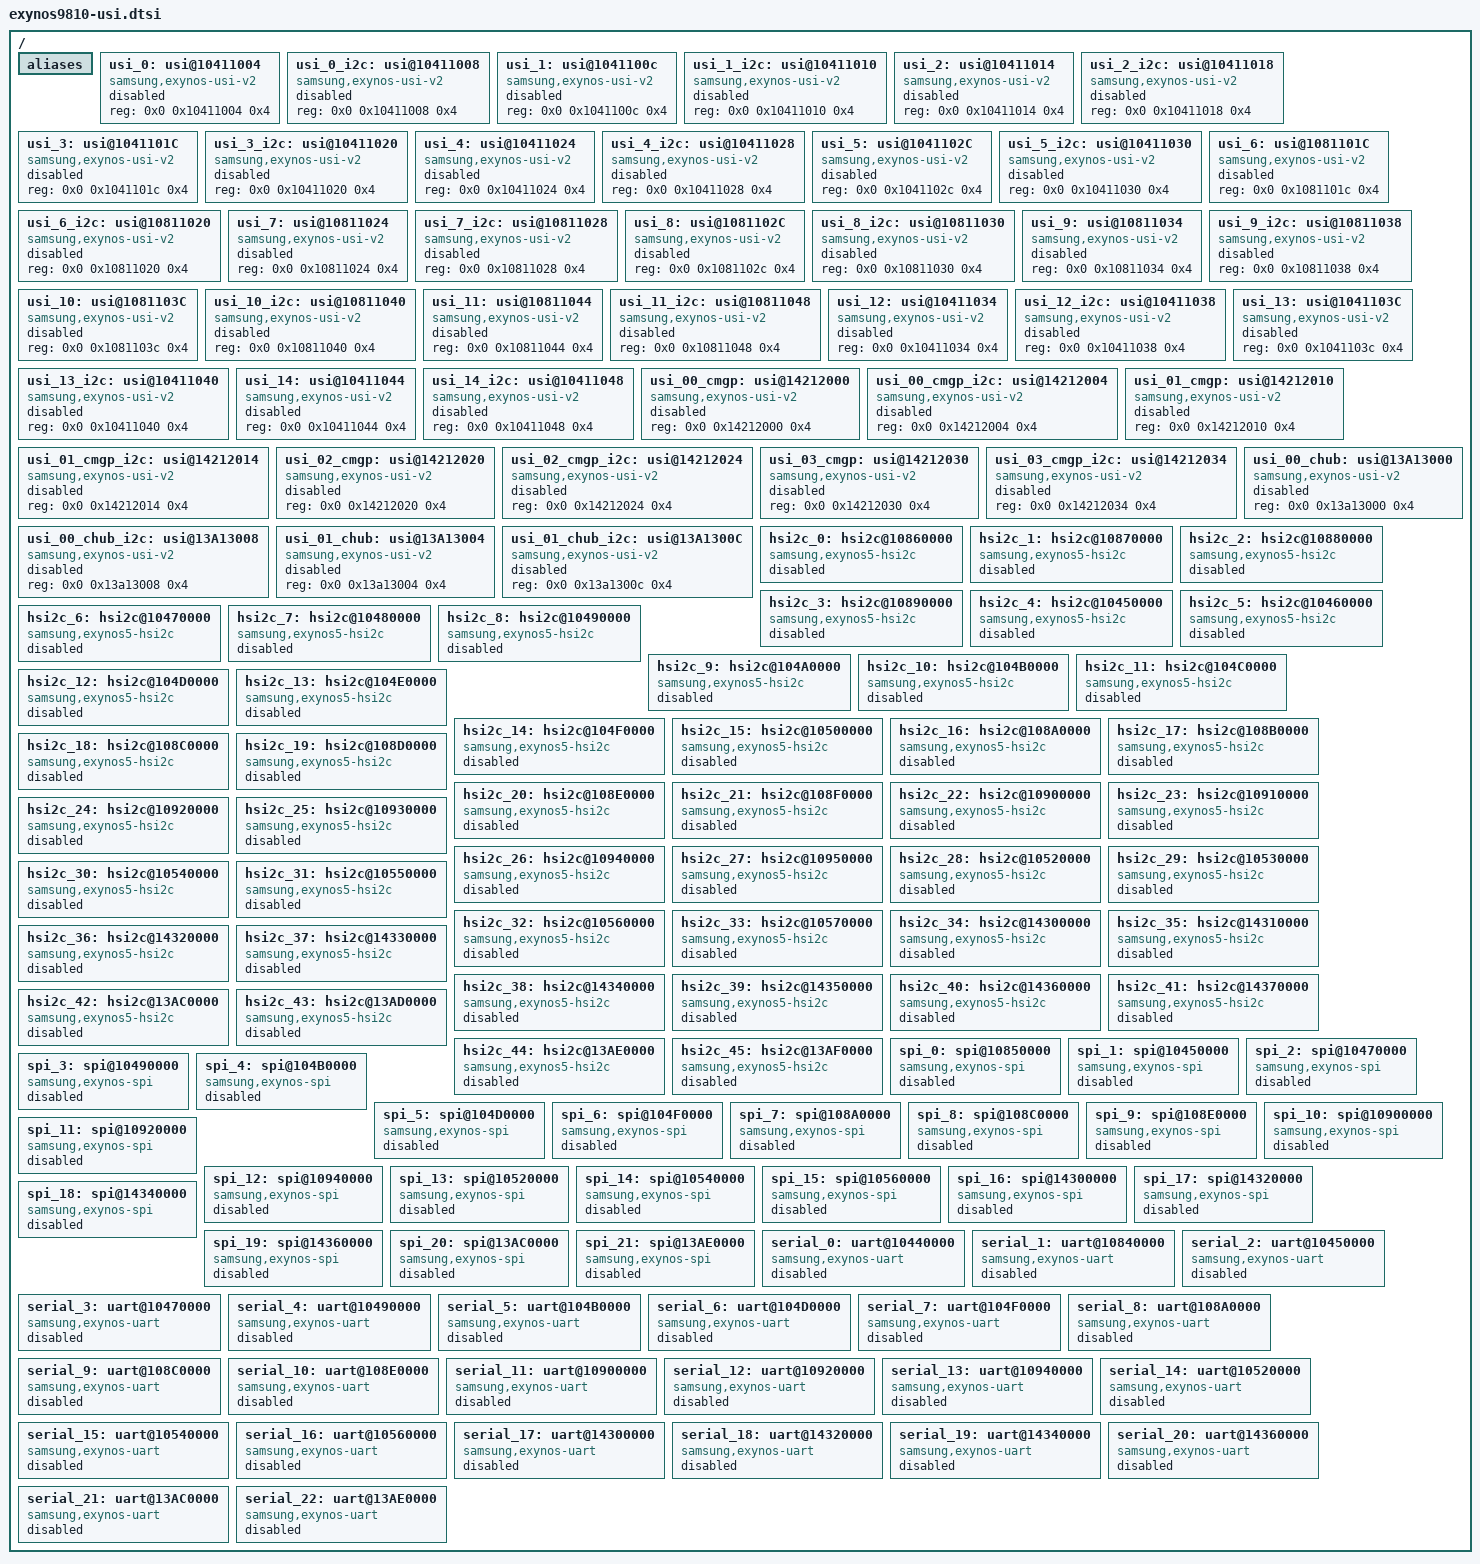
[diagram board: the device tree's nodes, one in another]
/*
 * SAMSUNG EXYNOS9810 SoC device tree source
 *
 * Copyright (c) 2017 Samsung Electronics Co., Ltd.
 *		http://www.samsung.com
 *
 * SAMSUNG EXYNOS9810 SoC device nodes are listed in this file.
 * EXYNOS9810 based board files can include this file and provide
 * values for board specfic bindings.
 *
 * This program is free software; you can redistribute it and/or modify
 * it under the terms of the GNU General Public License version 2 as
 * published by the Free Software Foundation.
 */

/ {
	aliases {
		usi0 = &usi_0;
		usi1 = &usi_0_i2c;
		usi2 = &usi_1;
		usi3 = &usi_1_i2c;
		usi4 = &usi_2;
		usi5 = &usi_2_i2c;
		usi6 = &usi_3;
		usi7 = &usi_3_i2c;
		usi8 = &usi_4;
		usi9 = &usi_4_i2c;
		usi10 = &usi_5;
		usi11 = &usi_5_i2c;
		usi12 = &usi_6;
		usi13 = &usi_6_i2c;
		usi14 = &usi_7;
		usi15 = &usi_7_i2c;
		usi16 = &usi_8;
		usi17 = &usi_8_i2c;
		usi18 = &usi_9;
		usi19 = &usi_9_i2c;
		usi20 = &usi_10;
		usi21 = &usi_10_i2c;
		usi22 = &usi_11;
		usi23 = &usi_11_i2c;
		usi24 = &usi_12;
		usi25 = &usi_12_i2c;
		usi26 = &usi_13;
		usi27 = &usi_13_i2c;
		usi28 = &usi_14;
		usi29 = &usi_14_i2c;
		usi30 = &usi_00_cmgp;
		usi31 = &usi_00_cmgp_i2c;
		usi32 = &usi_01_cmgp;
		usi33 = &usi_01_cmgp_i2c;
		usi34 = &usi_02_cmgp;
		usi35 = &usi_02_cmgp_i2c;
		usi36 = &usi_03_cmgp;
		usi37 = &usi_03_cmgp_i2c;
		usi38 = &usi_00_chub;
		usi39 = &usi_00_chub_i2c;
		usi40 = &usi_01_chub;
		usi41 = &usi_01_chub_i2c;
		hsi2c0 = &hsi2c_0;
		hsi2c1 = &hsi2c_1;
		hsi2c2 = &hsi2c_2;
		hsi2c3 = &hsi2c_3;
		hsi2c4 = &hsi2c_4;
		hsi2c5 = &hsi2c_5;
		hsi2c6 = &hsi2c_6;
		hsi2c7 = &hsi2c_7;
		hsi2c8 = &hsi2c_8;
		hsi2c9 = &hsi2c_9;
		hsi2c10 = &hsi2c_10;
		hsi2c11 = &hsi2c_11;
		hsi2c12 = &hsi2c_12;
		hsi2c13 = &hsi2c_13;
		hsi2c14 = &hsi2c_14;
		hsi2c15 = &hsi2c_15;
		hsi2c16 = &hsi2c_16;
		hsi2c17 = &hsi2c_17;
		hsi2c18 = &hsi2c_18;
		hsi2c19 = &hsi2c_19;
		hsi2c20 = &hsi2c_20;
		hsi2c21 = &hsi2c_21;
		hsi2c22 = &hsi2c_22;
		hsi2c23 = &hsi2c_23;
		hsi2c24 = &hsi2c_24;
		hsi2c25 = &hsi2c_25;
		hsi2c26 = &hsi2c_26;
		hsi2c27 = &hsi2c_27;
		hsi2c28 = &hsi2c_28;
		hsi2c29 = &hsi2c_29;
		hsi2c30 = &hsi2c_30;
		hsi2c31 = &hsi2c_31;
		hsi2c32 = &hsi2c_32;
		hsi2c33 = &hsi2c_33;
		hsi2c34 = &hsi2c_34;
		hsi2c35 = &hsi2c_35;
		hsi2c36 = &hsi2c_36;
		hsi2c37 = &hsi2c_37;
		hsi2c38 = &hsi2c_38;
		hsi2c39 = &hsi2c_39;
		hsi2c40 = &hsi2c_40;
		hsi2c41 = &hsi2c_41;
		hsi2c42 = &hsi2c_42;
		hsi2c43 = &hsi2c_43;
		hsi2c44 = &hsi2c_44;
		hsi2c45 = &hsi2c_45;
		spi0 = &spi_0;
		spi1 = &spi_1;
		spi2 = &spi_2;
		spi3 = &spi_3;
		spi4 = &spi_4;
		spi5 = &spi_5;
		spi6 = &spi_6;
		spi7 = &spi_7;
		spi8 = &spi_8;
		spi9 = &spi_9;
		spi10 = &spi_10;
		spi11 = &spi_11;
		spi12 = &spi_12;
		spi13 = &spi_13;
		spi14 = &spi_14;
		spi15 = &spi_15;
		spi16 = &spi_16;
		spi17 = &spi_17;
		spi18 = &spi_18;
		spi19 = &spi_19;
		spi20 = &spi_20;
		spi21 = &spi_21;
		uart0 = &serial_0;
		uart1 = &serial_1;
		uart2 = &serial_2;
		uart3 = &serial_3;
		uart4 = &serial_4;
		uart5 = &serial_5;
		uart6 = &serial_6;
		uart7 = &serial_7;
		uart8 = &serial_8;
		uart9 = &serial_9;
		uart10 = &serial_10;
		uart11 = &serial_11;
		uart12 = &serial_12;
		uart13 = &serial_13;
		uart14 = &serial_14;
		uart15 = &serial_15;
		uart16 = &serial_16;
		uart17 = &serial_17;
		uart18 = &serial_18;
		uart19 = &serial_19;
		uart20 = &serial_20;
		uart21 = &serial_21;
		uart22 = &serial_22;
	};

	/* USI_00 */
	usi_0: usi@10411004 {
		compatible = "samsung,exynos-usi-v2";
		reg = <0x0 0x10411004 0x4>;
		/*	usi_mode_v2 = "i2c" or "spi" or "uart"	*/
		status = "disabled";
	};

	/* USI_00_I2C */
	usi_0_i2c: usi@10411008 {
		compatible = "samsung,exynos-usi-v2";
		reg = <0x0 0x10411008 0x4>;
		/*	usi_mode_v2 = "i2c" */
		status = "disabled";
	};

	/* USI_01 */
	usi_1: usi@1041100c {
		compatible = "samsung,exynos-usi-v2";
		reg = <0x0 0x1041100c 0x4>;
		/*	usi_mode_v2 = "i2c" or "spi" or "uart"	*/
		status = "disabled";
	};

	/* USI_01_I2C */
	usi_1_i2c: usi@10411010 {
		compatible = "samsung,exynos-usi-v2";
		reg = <0x0 0x10411010 0x4>;
		/*	usi_mode_v2 = "i2c" */
		status = "disabled";
	};

	/* USI_02 */
	usi_2: usi@10411014 {
		compatible = "samsung,exynos-usi-v2";
		reg = <0x0 0x10411014 0x4>;
		/*	usi_mode_v2 = "i2c" or "spi" or "uart"	*/
		status = "disabled";
	};

	/* USI_02_I2C */
	usi_2_i2c: usi@10411018 {
		compatible = "samsung,exynos-usi-v2";
		reg = <0x0 0x10411018 0x4>;
		/*	usi_mode_v2 = "i2c" */
		status = "disabled";
	};

	/* USI_03 */
	usi_3: usi@1041101C {
		compatible = "samsung,exynos-usi-v2";
		reg = <0x0 0x1041101c 0x4>;
		/*	usi_mode_v2 = "i2c" or "spi" or "uart"	*/
		status = "disabled";
	};

	/* USI_03_I2C */
	usi_3_i2c: usi@10411020 {
		compatible = "samsung,exynos-usi-v2";
		reg = <0x0 0x10411020 0x4>;
		/*	usi_mode_v2 = "i2c" */
		status = "disabled";
	};

	/* USI_04 */
	usi_4: usi@10411024 {
		compatible = "samsung,exynos-usi-v2";
		reg = <0x0 0x10411024 0x4>;
		/*	usi_mode_v2 = "i2c" or "spi" or "uart"	*/
		status = "disabled";
	};

	/* USI_04_I2C */
	usi_4_i2c: usi@10411028 {
		compatible = "samsung,exynos-usi-v2";
		reg = <0x0 0x10411028 0x4>;
		/*	usi_mode_v2 = "i2c" */
		status = "disabled";
	};

	/* USI_05 */
	usi_5: usi@1041102C {
		compatible = "samsung,exynos-usi-v2";
		reg = <0x0 0x1041102c 0x4>;
		/*	usi_mode_v2 = "i2c" or "spi" or "uart"	*/
		status = "disabled";
	};

	/* USI_05_I2C */
	usi_5_i2c: usi@10411030 {
		compatible = "samsung,exynos-usi-v2";
		reg = <0x0 0x10411030 0x4>;
		/*	usi_mode_v2 = "i2c" */
		status = "disabled";
	};

	/* USI_06 */
	usi_6: usi@1081101C {
		compatible = "samsung,exynos-usi-v2";
		reg = <0x0 0x1081101c 0x4>;
		/*	usi_mode_v2 = "i2c" or "spi" or "uart"	*/
		status = "disabled";
	};

	/* USI_06_I2C */
	usi_6_i2c: usi@10811020 {
		compatible = "samsung,exynos-usi-v2";
		reg = <0x0 0x10811020 0x4>;
		/*	usi_mode_v2 = "i2c" */
		status = "disabled";
	};

	/* USI_07 */
	usi_7: usi@10811024 {
		compatible = "samsung,exynos-usi-v2";
		reg = <0x0 0x10811024 0x4>;
		/*	usi_mode_v2 = "i2c" or "spi" or "uart"	*/
		status = "disabled";
	};

	/* USI_07_I2C */
	usi_7_i2c: usi@10811028 {
		compatible = "samsung,exynos-usi-v2";
		reg = <0x0 0x10811028 0x4>;
		/*	usi_mode_v2 = "i2c" */
		status = "disabled";
	};

	/* USI_08 */
	usi_8: usi@1081102C {
		compatible = "samsung,exynos-usi-v2";
		reg = <0x0 0x1081102c 0x4>;
		/*	usi_mode_v2 = "i2c" or "spi" or "uart"	*/
		status = "disabled";
	};

	/* USI_08_I2C */
	usi_8_i2c: usi@10811030 {
		compatible = "samsung,exynos-usi-v2";
		reg = <0x0 0x10811030 0x4>;
		/*	usi_mode_v2 = "i2c" */
		status = "disabled";
	};

	/* USI_09 */
	usi_9: usi@10811034 {
		compatible = "samsung,exynos-usi-v2";
		reg = <0x0 0x10811034 0x4>;
		/*	usi_mode_v2 = "i2c" or "spi" or "uart"	*/
		status = "disabled";
	};

	/* USI_09_I2C */
	usi_9_i2c: usi@10811038 {
		compatible = "samsung,exynos-usi-v2";
		reg = <0x0 0x10811038 0x4>;
		/*	usi_mode_v2 = "i2c" */
		status = "disabled";
	};

	/* USI_10 */
	usi_10: usi@1081103C {
		compatible = "samsung,exynos-usi-v2";
		reg = <0x0 0x1081103c 0x4>;
		/*	usi_mode_v2 = "i2c" or "spi" or "uart"	*/
		status = "disabled";
	};

	/* USI_10_I2C */
	usi_10_i2c: usi@10811040 {
		compatible = "samsung,exynos-usi-v2";
		reg = <0x0 0x10811040 0x4>;
		/*	usi_mode_v2 = "i2c" */
		status = "disabled";
	};

	/* USI_11 */
	usi_11: usi@10811044 {
		compatible = "samsung,exynos-usi-v2";
		reg = <0x0 0x10811044 0x4>;
		/*	usi_mode_v2 = "i2c" or "spi" or "uart"	*/
		status = "disabled";
	};

	/* USI_11_I2C */
	usi_11_i2c: usi@10811048 {
		compatible = "samsung,exynos-usi-v2";
		reg = <0x0 0x10811048 0x4>;
		/*	usi_mode_v2 = "i2c" */
		status = "disabled";
	};

	/* USI_12 */
	usi_12: usi@10411034 {
		compatible = "samsung,exynos-usi-v2";
		reg = <0x0 0x10411034 0x4>;
		/*	usi_mode_v2 = "i2c" or "spi" or "uart"	*/
		status = "disabled";
	};

	/* USI_12_I2C */
	usi_12_i2c: usi@10411038 {
		compatible = "samsung,exynos-usi-v2";
		reg = <0x0 0x10411038 0x4>;
		/*	usi_mode_v2 = "i2c" */
		status = "disabled";
	};

	/* USI_13 */
	usi_13: usi@1041103C {
		compatible = "samsung,exynos-usi-v2";
		reg = <0x0 0x1041103c 0x4>;
		/*	usi_mode_v2 = "i2c" or "spi" or "uart"	*/
		status = "disabled";
	};

	/* USI_13_I2C */
	usi_13_i2c: usi@10411040 {
		compatible = "samsung,exynos-usi-v2";
		reg = <0x0 0x10411040 0x4>;
		/*	usi_mode_v2 = "i2c" */
		status = "disabled";
	};

	/* USI_14 */
	usi_14: usi@10411044 {
		compatible = "samsung,exynos-usi-v2";
		reg = <0x0 0x10411044 0x4>;
		/*	usi_mode_v2 = "i2c" or "spi" or "uart"	*/
		status = "disabled";
	};

	/* USI_14_I2C */
	usi_14_i2c: usi@10411048 {
		compatible = "samsung,exynos-usi-v2";
		reg = <0x0 0x10411048 0x4>;
		/*	usi_mode_v2 = "i2c" */
		status = "disabled";
	};

	/* USI_00_CMGP */
	usi_00_cmgp: usi@14212000 {
		compatible = "samsung,exynos-usi-v2";
		reg = <0x0 0x14212000 0x4>;
		/*	usi_mode_v2 = "i2c" or "spi" or "uart"	*/
		status = "disabled";
	};

	/* USI_00_CMGP_I2C */
	usi_00_cmgp_i2c: usi@14212004 {
		compatible = "samsung,exynos-usi-v2";
		reg = <0x0 0x14212004 0x4>;
		/*	usi_mode_v2 = "i2c" */
		status = "disabled";
	};

	/* USI_01_CMGP */
	usi_01_cmgp: usi@14212010 {
		compatible = "samsung,exynos-usi-v2";
		reg = <0x0 0x14212010 0x4>;
		/*	usi_mode_v2 = "i2c" or "spi" or "uart"	*/
		status = "disabled";
	};

	/* USI_01_CMGP_I2C */
	usi_01_cmgp_i2c: usi@14212014 {
		compatible = "samsung,exynos-usi-v2";
		reg = <0x0 0x14212014 0x4>;
		/*	usi_mode_v2 = "i2c" */
		status = "disabled";
	};

	/* USI_02_CMGP */
	usi_02_cmgp: usi@14212020 {
		compatible = "samsung,exynos-usi-v2";
		reg = <0x0 0x14212020 0x4>;
		/*	usi_mode_v2 = "i2c" or "spi" or "uart"	*/
		status = "disabled";
	};

	/* USI_02_CMGP_I2C */
	usi_02_cmgp_i2c: usi@14212024 {
		compatible = "samsung,exynos-usi-v2";
		reg = <0x0 0x14212024 0x4>;
		/*	usi_mode_v2 = "i2c" */
		status = "disabled";
	};

	/* USI_03_CMGP */
	usi_03_cmgp: usi@14212030 {
		compatible = "samsung,exynos-usi-v2";
		reg = <0x0 0x14212030 0x4>;
		/*	usi_mode_v2 = "i2c" or "spi" or "uart"	*/
		status = "disabled";
	};

	/* USI_03_CMGP_I2C */
	usi_03_cmgp_i2c: usi@14212034 {
		compatible = "samsung,exynos-usi-v2";
		reg = <0x0 0x14212034 0x4>;
		/*	usi_mode_v2 = "i2c" */
		status = "disabled";
	};

	/* USI_00_CHUB */
	usi_00_chub: usi@13A13000 {
		compatible = "samsung,exynos-usi-v2";
		reg = <0x0 0x13a13000 0x4>;
		/*	usi_mode_v2 = "i2c" */
		status = "disabled";
	};

	/* USI_00_CHUB_I2C */
	usi_00_chub_i2c: usi@13A13008 {
		compatible = "samsung,exynos-usi-v2";
		reg = <0x0 0x13a13008 0x4>;
		/*	usi_mode_v2 = "i2c" */
		status = "disabled";
	};

	/* USI_01_CHUB */
	usi_01_chub: usi@13A13004 {
		compatible = "samsung,exynos-usi-v2";
		reg = <0x0 0x13a13004 0x4>;
		/*	usi_mode_v2 = "i2c" */
		status = "disabled";
	};

	/* USI_01_CHUB_I2C */
	usi_01_chub_i2c: usi@13A1300C {
		compatible = "samsung,exynos-usi-v2";
		reg = <0x0 0x13a1300c 0x4>;
		/*	usi_mode_v2 = "i2c" */
		status = "disabled";
	};

	/* PERIC1 CAM0 */
	hsi2c_0: hsi2c@10860000 {
		compatible = "samsung,exynos5-hsi2c";
		samsung,check-transdone-int;
		default-clk = <200000000>;
		reg = <0x0 0x10860000 0x1000>;
		interrupts = <0 INTREQ__I2C_CAM0 0>;
		#address-cells = <1>;
		#size-cells = <0>;
		pinctrl-names = "default";
		pinctrl-0 = <&hsi2c0_bus>;
		clocks = <&clock I2C_CAM0>, <&clock GATE_I2C_CAM0>;
		clock-names = "rate_hsi2c", "gate_hsi2c";
		samsung,scl-clk-stretching;
		samsung,usi-i2c-v2;
		gpio_scl= <&gpc0 0 0x1>;
		gpio_sda= <&gpc0 1 0x1>;
		status = "disabled";
	};

	/* PERI1 CAM1 */
	hsi2c_1: hsi2c@10870000 {
		compatible = "samsung,exynos5-hsi2c";
		samsung,check-transdone-int;
		default-clk = <200000000>;
		reg = <0x0 0x10870000 0x1000>;
		interrupts = <0 INTREQ__I2C_CAM1 0>;
		#address-cells = <1>;
		#size-cells = <0>;
		pinctrl-names = "default";
		pinctrl-0 = <&hsi2c1_bus>;
		clocks = <&clock I2C_CAM1>, <&clock GATE_I2C_CAM1>;
		clock-names = "rate_hsi2c", "gate_hsi2c";
		samsung,scl-clk-stretching;
		samsung,usi-i2c-v2;
		gpio_scl= <&gpc0 2 0x1>;
		gpio_sda= <&gpc0 3 0x1>;
		status = "disabled";
	};

	/* PERI1 CAM2 */
	hsi2c_2: hsi2c@10880000 {
		compatible = "samsung,exynos5-hsi2c";
		samsung,check-transdone-int;
		default-clk = <200000000>;
		reg = <0x0 0x10880000 0x1000>;
		interrupts = <0 INTREQ__I2C_CAM2 0>;
		#address-cells = <1>;
		#size-cells = <0>;
		pinctrl-names = "default";
		pinctrl-0 = <&hsi2c2_bus>;
		clocks = <&clock I2C_CAM2>, <&clock GATE_I2C_CAM2>;
		clock-names = "rate_hsi2c", "gate_hsi2c";
		samsung,scl-clk-stretching;
		samsung,usi-i2c-v2;
		gpio_scl= <&gpc0 4 0x1>;
		gpio_sda= <&gpc0 5 0x1>;
		status = "disabled";
	};

	/* PERI1 CAM3 */
	hsi2c_3: hsi2c@10890000 {
		compatible = "samsung,exynos5-hsi2c";
		samsung,check-transdone-int;
		default-clk = <200000000>;
		reg = <0x0 0x10890000 0x1000>;
		interrupts = <0 INTREQ__I2C_CAM3 0>;
		#address-cells = <1>;
		#size-cells = <0>;
		pinctrl-names = "default";
		pinctrl-0 = <&hsi2c3_bus>;
		clocks = <&clock I2C_CAM3>, <&clock GATE_I2C_CAM3>;
		clock-names = "rate_hsi2c", "gate_hsi2c";
		samsung,scl-clk-stretching;
		samsung,usi-i2c-v2;
		gpio_scl= <&gpc0 6 0x1>;
		gpio_sda= <&gpc0 7 0x1>;
		status = "disabled";
	};

	/* USI00_USI */
	hsi2c_4: hsi2c@10450000 {
		compatible = "samsung,exynos5-hsi2c";
		samsung,check-transdone-int;
		default-clk = <200000000>;
		reg = <0x0 0x10450000 0x1000>;
		interrupts = <0 INTREQ__USI00_USI 0>;
		#address-cells = <1>;
		#size-cells = <0>;
		pinctrl-names = "default";
		pinctrl-0 = <&hsi2c4_bus>;
		clocks = <&clock USI00>, <&clock GATE_USI00>;
		clock-names = "rate_hsi2c", "gate_hsi2c";
		samsung,scl-clk-stretching;
		samsung,usi-i2c-v2;
		gpio_scl= <&gpp0 0 0x1>;
		gpio_sda= <&gpp0 1 0x1>;
		status = "disabled";
	};

	/* USI00_USI_I2C */
	hsi2c_5: hsi2c@10460000 {
		compatible = "samsung,exynos5-hsi2c";
		samsung,check-transdone-int;
		default-clk = <200000000>;
		reg = <0x0 0x10460000 0x1000>;
		interrupts = <0 INTREQ__USI00_I2C 0>;
		#address-cells = <1>;
		#size-cells = <0>;
		pinctrl-names = "default";
		pinctrl-0 = <&hsi2c5_bus>;
		clocks = <&clock PERIC0_USI_I2C>, <&clock GATE_USI00_I2C>;
		clock-names = "rate_hsi2c", "gate_hsi2c";
		samsung,scl-clk-stretching;
		samsung,usi-i2c-v2;
		gpio_scl= <&gpp0 2 0x1>;
		gpio_sda= <&gpp0 3 0x1>;
		status = "disabled";
	};

	/* USI01_USI */
	hsi2c_6: hsi2c@10470000 {
		compatible = "samsung,exynos5-hsi2c";
		samsung,check-transdone-int;
		default-clk = <200000000>;
		reg = <0x0 0x10470000 0x1000>;
		interrupts = <0 INTREQ__USI01_USI 0>;
		#address-cells = <1>;
		#size-cells = <0>;
		pinctrl-names = "default";
		pinctrl-0 = <&hsi2c6_bus>;
		clocks = <&clock USI01>, <&clock GATE_USI01>;
		clock-names = "rate_hsi2c", "gate_hsi2c";
		samsung,scl-clk-stretching;
		samsung,usi-i2c-v2;
		gpio_scl= <&gpp0 4 0x1>;
		gpio_sda= <&gpp0 5 0x1>;
		status = "disabled";
	};

	/* USI01_USI_I2C */
	hsi2c_7: hsi2c@10480000 {
		compatible = "samsung,exynos5-hsi2c";
		samsung,check-transdone-int;
		default-clk = <200000000>;
		reg = <0x0 0x10480000 0x1000>;
		interrupts = <0 INTREQ__USI01_I2C 0>;
		#address-cells = <1>;
		#size-cells = <0>;
		pinctrl-names = "default";
		pinctrl-0 = <&hsi2c7_bus>;
		clocks = <&clock PERIC0_USI_I2C>, <&clock GATE_USI01_I2C>;
		clock-names = "rate_hsi2c", "gate_hsi2c";
		samsung,scl-clk-stretching;
		samsung,usi-i2c-v2;
		gpio_scl= <&gpp0 6 0x1>;
		gpio_sda= <&gpp0 7 0x1>;
		status = "disabled";
	};

	/* USI02_USI */
	hsi2c_8: hsi2c@10490000 {
		compatible = "samsung,exynos5-hsi2c";
		samsung,check-transdone-int;
		default-clk = <200000000>;
		reg = <0x0 0x10490000 0x1000>;
		interrupts = <0 INTREQ__USI02_USI 0>;
		#address-cells = <1>;
		#size-cells = <0>;
		pinctrl-names = "default";
		pinctrl-0 = <&hsi2c8_bus>;
		clocks = <&clock USI02>, <&clock GATE_USI02>;
		clock-names = "rate_hsi2c", "gate_hsi2c";
		samsung,scl-clk-stretching;
		samsung,usi-i2c-v2;
		gpio_scl= <&gpp1 0 0x1>;
		gpio_sda= <&gpp1 1 0x1>;
		status = "disabled";
	};

	/* USI02_USI_I2C */
	hsi2c_9: hsi2c@104A0000 {
		compatible = "samsung,exynos5-hsi2c";
		samsung,check-transdone-int;
		default-clk = <200000000>;
		reg = <0x0 0x104a0000 0x1000>;
		interrupts = <0 INTREQ__USI02_I2C 0>;
		#address-cells = <1>;
		#size-cells = <0>;
		pinctrl-names = "default";
		pinctrl-0 = <&hsi2c9_bus>;
		clocks = <&clock PERIC0_USI_I2C>, <&clock GATE_USI02_I2C>;
		clock-names = "rate_hsi2c", "gate_hsi2c";
		samsung,scl-clk-stretching;
		samsung,usi-i2c-v2;
		gpio_scl= <&gpp1 2 0x1>;
		gpio_sda= <&gpp1 3 0x1>;
		status = "disabled";
	};

	/* USI03_USI */
	hsi2c_10: hsi2c@104B0000 {
		compatible = "samsung,exynos5-hsi2c";
		samsung,check-transdone-int;
		default-clk = <200000000>;
		reg = <0x0 0x104B0000 0x1000>;
		interrupts = <0 INTREQ__USI03_USI 0>;
		#address-cells = <1>;
		#size-cells = <0>;
		pinctrl-names = "default";
		pinctrl-0 = <&hsi2c10_bus>;
		clocks = <&clock USI03>, <&clock GATE_USI03>;
		clock-names = "rate_hsi2c", "gate_hsi2c";
		samsung,scl-clk-stretching;
		samsung,usi-i2c-v2;
		gpio_scl= <&gpp1 4 0x1>;
		gpio_sda= <&gpp1 5 0x1>;
		status = "disabled";
	};

	/* USI03_USI_I2C */
	hsi2c_11: hsi2c@104C0000 {
		compatible = "samsung,exynos5-hsi2c";
		samsung,check-transdone-int;
		default-clk = <200000000>;
		reg = <0x0 0x104C0000 0x1000>;
		interrupts = <0 INTREQ__USI03_I2C 0>;
		#address-cells = <1>;
		#size-cells = <0>;
		pinctrl-names = "default";
		pinctrl-0 = <&hsi2c11_bus>;
		clocks = <&clock PERIC0_USI_I2C>, <&clock GATE_USI03_I2C>;
		clock-names = "rate_hsi2c", "gate_hsi2c";
		samsung,scl-clk-stretching;
		samsung,usi-i2c-v2;
		gpio_scl= <&gpp1 6 0x1>;
		gpio_sda= <&gpp1 7 0x1>;
		status = "disabled";
	};

	/* USI04_USI */
	hsi2c_12: hsi2c@104D0000 {
		compatible = "samsung,exynos5-hsi2c";
		samsung,check-transdone-int;
		default-clk = <200000000>;
		reg = <0x0 0x104D0000 0x1000>;
		interrupts = <0 INTREQ__USI04_USI 0>;
		#address-cells = <1>;
		#size-cells = <0>;
		pinctrl-names = "default";
		pinctrl-0 = <&hsi2c12_bus>;
		clocks = <&clock USI04>, <&clock GATE_USI04>;
		clock-names = "rate_hsi2c", "gate_hsi2c";
		samsung,scl-clk-stretching;
		samsung,usi-i2c-v2;
		gpio_scl= <&gpp2 0 0x1>;
		gpio_sda= <&gpp2 1 0x1>;
		status = "disabled";
	};

	/* USI04_USI_I2C */
	hsi2c_13: hsi2c@104E0000 {
		compatible = "samsung,exynos5-hsi2c";
		samsung,check-transdone-int;
		default-clk = <200000000>;
		reg = <0x0 0x104E0000 0x1000>;
		interrupts = <0 INTREQ__USI04_I2C 0>;
		#address-cells = <1>;
		#size-cells = <0>;
		pinctrl-names = "default";
		pinctrl-0 = <&hsi2c13_bus>;
		clocks = <&clock PERIC0_USI_I2C>, <&clock GATE_USI04_I2C>;
		clock-names = "rate_hsi2c", "gate_hsi2c";
		samsung,scl-clk-stretching;
		samsung,usi-i2c-v2;
		gpio_scl= <&gpp2 2 0x1>;
		gpio_sda= <&gpp2 3 0x1>;
		status = "disabled";
	};

	/* USI05_USI */
	hsi2c_14: hsi2c@104F0000 {
		compatible = "samsung,exynos5-hsi2c";
		samsung,check-transdone-int;
		default-clk = <200000000>;
		reg = <0x0 0x104F0000 0x1000>;
		interrupts = <0 INTREQ__USI05_USI 0>;
		#address-cells = <1>;
		#size-cells = <0>;
		pinctrl-names = "default";
		pinctrl-0 = <&hsi2c14_bus>;
		clocks = <&clock USI05>, <&clock GATE_USI05>;
		clock-names = "rate_hsi2c", "gate_hsi2c";
		samsung,scl-clk-stretching;
		samsung,usi-i2c-v2;
		gpio_scl= <&gpp2 4 0x1>;
		gpio_sda= <&gpp2 5 0x1>;
		status = "disabled";
	};

	/* USI05_USI_I2C */
	hsi2c_15: hsi2c@10500000 {
		compatible = "samsung,exynos5-hsi2c";
		samsung,check-transdone-int;
		default-clk = <200000000>;
		reg = <0x0 0x10500000 0x1000>;
		interrupts = <0 INTREQ__USI05_I2C 0>;
		#address-cells = <1>;
		#size-cells = <0>;
		pinctrl-names = "default";
		pinctrl-0 = <&hsi2c15_bus>;
		clocks = <&clock PERIC0_USI_I2C>, <&clock GATE_USI05_I2C>;
		clock-names = "rate_hsi2c", "gate_hsi2c";
		samsung,scl-clk-stretching;
		samsung,usi-i2c-v2;
		gpio_scl= <&gpp2 6 0x1>;
		gpio_sda= <&gpp2 7 0x1>;
		status = "disabled";
	};

	/* USI06_USI */
	hsi2c_16: hsi2c@108A0000 {
		compatible = "samsung,exynos5-hsi2c";
		samsung,check-transdone-int;
		default-clk = <200000000>;
		reg = <0x0 0x108A0000 0x1000>;
		interrupts = <0 INTREQ__USI06_USI 0>;
		#address-cells = <1>;
		#size-cells = <0>;
		pinctrl-names = "default";
		pinctrl-0 = <&hsi2c16_bus>;
		clocks = <&clock USI06>, <&clock GATE_USI06>;
		clock-names = "rate_hsi2c", "gate_hsi2c";
		samsung,scl-clk-stretching;
		samsung,usi-i2c-v2;
		gpio_scl= <&gpp4 0 0x1>;
		gpio_sda= <&gpp4 1 0x1>;
		status = "disabled";
	};

	/* USI06_USI_I2C */
	hsi2c_17: hsi2c@108B0000 {
		compatible = "samsung,exynos5-hsi2c";
		samsung,check-transdone-int;
		default-clk = <200000000>;
		reg = <0x0 0x108B0000 0x1000>;
		interrupts = <0 INTREQ__USI06_I2C 0>;
		#address-cells = <1>;
		#size-cells = <0>;
		pinctrl-names = "default";
		pinctrl-0 = <&hsi2c17_bus>;
		clocks = <&clock PERIC1_USI_I2C>, <&clock GATE_USI06_I2C>;
		clock-names = "rate_hsi2c", "gate_hsi2c";
		samsung,scl-clk-stretching;
		samsung,usi-i2c-v2;
		gpio_scl= <&gpp4 2 0x1>;
		gpio_sda= <&gpp4 3 0x1>;
		status = "disabled";
	};

	/* USI07_USI */
	hsi2c_18: hsi2c@108C0000 {
		compatible = "samsung,exynos5-hsi2c";
		samsung,check-transdone-int;
		default-clk = <200000000>;
		reg = <0x0 0x108C0000 0x1000>;
		interrupts = <0 INTREQ__USI07_USI 0>;
		#address-cells = <1>;
		#size-cells = <0>;
		pinctrl-names = "default";
		pinctrl-0 = <&hsi2c18_bus>;
		clocks = <&clock USI07>, <&clock GATE_USI07>;
		clock-names = "rate_hsi2c", "gate_hsi2c";
		samsung,scl-clk-stretching;
		samsung,usi-i2c-v2;
		gpio_scl= <&gpp4 4 0x1>;
		gpio_sda= <&gpp4 5 0x1>;
		status = "disabled";
	};

	/* USI07_USI_I2C */
	hsi2c_19: hsi2c@108D0000 {
		compatible = "samsung,exynos5-hsi2c";
		samsung,check-transdone-int;
		default-clk = <200000000>;
		reg = <0x0 0x108D0000 0x1000>;
		interrupts = <0 INTREQ__USI07_I2C 0>;
		#address-cells = <1>;
		#size-cells = <0>;
		pinctrl-names = "default";
		pinctrl-0 = <&hsi2c19_bus>;
		clocks = <&clock PERIC1_USI_I2C>, <&clock GATE_USI07_I2C>;
		clock-names = "rate_hsi2c", "gate_hsi2c";
		samsung,scl-clk-stretching;
		samsung,usi-i2c-v2;
		gpio_scl= <&gpp4 6 0x1>;
		gpio_sda= <&gpp4 7 0x1>;
		status = "disabled";
	};

	/* USI08_USI */
	hsi2c_20: hsi2c@108E0000 {
		compatible = "samsung,exynos5-hsi2c";
		samsung,check-transdone-int;
		default-clk = <200000000>;
		reg = <0x0 0x108E0000 0x1000>;
		interrupts = <0 INTREQ__USI08_USI 0>;
		#address-cells = <1>;
		#size-cells = <0>;
		pinctrl-names = "default";
		pinctrl-0 = <&hsi2c20_bus>;
		clocks = <&clock USI08>, <&clock GATE_USI08>;
		clock-names = "rate_hsi2c", "gate_hsi2c";
		samsung,scl-clk-stretching;
		samsung,usi-i2c-v2;
		gpio_scl= <&gpp5 0 0x1>;
		gpio_sda= <&gpp5 1 0x1>;
		status = "disabled";
	};

	/* USI08_USI_I2C */
	hsi2c_21: hsi2c@108F0000 {
		compatible = "samsung,exynos5-hsi2c";
		samsung,check-transdone-int;
		default-clk = <200000000>;
		reg = <0x0 0x108F0000 0x1000>;
		interrupts = <0 INTREQ__USI08_I2C 0>;
		#address-cells = <1>;
		#size-cells = <0>;
		pinctrl-names = "default";
		pinctrl-0 = <&hsi2c21_bus>;
		clocks = <&clock PERIC1_USI_I2C>, <&clock GATE_USI08_I2C>;
		clock-names = "rate_hsi2c", "gate_hsi2c";
		samsung,scl-clk-stretching;
		samsung,usi-i2c-v2;
		gpio_scl= <&gpp5 2 0x1>;
		gpio_sda= <&gpp5 3 0x1>;
		status = "disabled";
	};

	/* USI09_USI */
	hsi2c_22: hsi2c@10900000 {
		compatible = "samsung,exynos5-hsi2c";
		samsung,check-transdone-int;
		default-clk = <200000000>;
		reg = <0x0 0x10900000 0x1000>;
		interrupts = <0 INTREQ__USI09_USI 0>;
		#address-cells = <1>;
		#size-cells = <0>;
		pinctrl-names = "default";
		pinctrl-0 = <&hsi2c22_bus>;
		clocks = <&clock USI09>, <&clock GATE_USI09>;
		clock-names = "rate_hsi2c", "gate_hsi2c";
		samsung,scl-clk-stretching;
		samsung,usi-i2c-v2;
		gpio_scl= <&gpp5 4 0x1>;
		gpio_sda= <&gpp5 5 0x1>;
		status = "disabled";
	};

	/* USI09_USI_I2C */
	hsi2c_23: hsi2c@10910000 {
		compatible = "samsung,exynos5-hsi2c";
		samsung,check-transdone-int;
		default-clk = <200000000>;
		reg = <0x0 0x10910000 0x1000>;
		interrupts = <0 INTREQ__USI09_I2C 0>;
		#address-cells = <1>;
		#size-cells = <0>;
		pinctrl-names = "default";
		pinctrl-0 = <&hsi2c23_bus>;
		clocks = <&clock PERIC1_USI_I2C>, <&clock GATE_USI09_I2C>;
		clock-names = "rate_hsi2c", "gate_hsi2c";
		samsung,scl-clk-stretching;
		samsung,usi-i2c-v2;
		gpio_scl= <&gpp5 6 0x1>;
		gpio_sda= <&gpp5 7 0x1>;
		status = "disabled";
	};

	/* USI10_USI */
	hsi2c_24: hsi2c@10920000 {
		compatible = "samsung,exynos5-hsi2c";
		samsung,check-transdone-int;
		default-clk = <200000000>;
		reg = <0x0 0x10920000 0x1000>;
		interrupts = <0 INTREQ__USI10_USI 0>;
		#address-cells = <1>;
		#size-cells = <0>;
		pinctrl-names = "default";
		pinctrl-0 = <&hsi2c24_bus>;
		clocks = <&clock USI10>, <&clock GATE_USI10>;
		clock-names = "rate_hsi2c", "gate_hsi2c";
		samsung,scl-clk-stretching;
		samsung,usi-i2c-v2;
		gpio_scl= <&gpp6 0 0x1>;
		gpio_sda= <&gpp6 1 0x1>;
		status = "disabled";
	};

	/* USI10_USI_I2C */
	hsi2c_25: hsi2c@10930000 {
		compatible = "samsung,exynos5-hsi2c";
		samsung,check-transdone-int;
		default-clk = <200000000>;
		reg = <0x0 0x10930000 0x1000>;
		interrupts = <0 INTREQ__USI10_I2C 0>;
		#address-cells = <1>;
		#size-cells = <0>;
		pinctrl-names = "default";
		pinctrl-0 = <&hsi2c25_bus>;
		clocks = <&clock PERIC1_USI_I2C>, <&clock GATE_USI10_I2C>;
		clock-names = "rate_hsi2c", "gate_hsi2c";
		samsung,scl-clk-stretching;
		samsung,usi-i2c-v2;
		gpio_scl= <&gpp6 2 0x1>;
		gpio_sda= <&gpp6 3 0x1>;
		status = "disabled";
	};

	/* USI11_USI */
	hsi2c_26: hsi2c@10940000 {
		compatible = "samsung,exynos5-hsi2c";
		samsung,check-transdone-int;
		default-clk = <200000000>;
		reg = <0x0 0x10940000 0x1000>;
		interrupts = <0 INTREQ__USI11_USI 0>;
		#address-cells = <1>;
		#size-cells = <0>;
		pinctrl-names = "default";
		pinctrl-0 = <&hsi2c26_bus>;
		clocks = <&clock USI11>, <&clock GATE_USI11>;
		clock-names = "rate_hsi2c", "gate_hsi2c";
		samsung,scl-clk-stretching;
		samsung,usi-i2c-v2;
		gpio_scl= <&gpg3 3 0x1>;
		gpio_sda= <&gpg3 4 0x1>;
		status = "disabled";
	};

	/* USI11_USI_I2C */
	hsi2c_27: hsi2c@10950000 {
		compatible = "samsung,exynos5-hsi2c";
		samsung,check-transdone-int;
		default-clk = <200000000>;
		reg = <0x0 0x10950000 0x1000>;
		interrupts = <0 INTREQ__USI11_I2C 0>;
		#address-cells = <1>;
		#size-cells = <0>;
		pinctrl-names = "default";
		pinctrl-0 = <&hsi2c27_bus>;
		clocks = <&clock PERIC1_USI_I2C>, <&clock GATE_USI11_I2C>;
		clock-names = "rate_hsi2c", "gate_hsi2c";
		samsung,scl-clk-stretching;
		samsung,usi-i2c-v2;
		gpio_scl= <&gpg3 5 0x1>;
		gpio_sda= <&gpg3 6 0x1>;
		status = "disabled";
	};

	/* USI12_USI */
	hsi2c_28: hsi2c@10520000 {
		compatible = "samsung,exynos5-hsi2c";
		samsung,check-transdone-int;
		default-clk = <200000000>;
		reg = <0x0 0x10520000 0x1000>;
		interrupts = <0 INTREQ__USI12_USI 0>;
		#address-cells = <1>;
		#size-cells = <0>;
		pinctrl-names = "default";
		pinctrl-0 = <&hsi2c28_bus>;
		clocks = <&clock USI12>, <&clock GATE_USI12>;
		clock-names = "rate_hsi2c", "gate_hsi2c";
		samsung,scl-clk-stretching;
		samsung,usi-i2c-v2;
		gpio_scl= <&gpg0 4 0x1>;
		gpio_sda= <&gpg0 5 0x1>;
		status = "disabled";
	};

	/* USI12_USI_I2C */
	hsi2c_29: hsi2c@10530000 {
		compatible = "samsung,exynos5-hsi2c";
		samsung,check-transdone-int;
		default-clk = <200000000>;
		reg = <0x0 0x10530000 0x1000>;
		interrupts = <0 INTREQ__USI12_I2C 0>;
		#address-cells = <1>;
		#size-cells = <0>;
		pinctrl-names = "default";
		pinctrl-0 = <&hsi2c29_bus>;
		clocks = <&clock PERIC0_USI_I2C>, <&clock GATE_USI12_I2C>;
		clock-names = "rate_hsi2c", "gate_hsi2c";
		samsung,scl-clk-stretching;
		samsung,usi-i2c-v2;
		gpio_scl= <&gpg0 6 0x1>;
		gpio_sda= <&gpg0 7 0x1>;
		status = "disabled";
	};

	/* USI13_USI */
	hsi2c_30: hsi2c@10540000 {
		compatible = "samsung,exynos5-hsi2c";
		samsung,check-transdone-int;
		default-clk = <200000000>;
		reg = <0x0 0x10540000 0x1000>;
		interrupts = <0 INTREQ__USI13_USI 0>;
		#address-cells = <1>;
		#size-cells = <0>;
		pinctrl-names = "default";
		pinctrl-0 = <&hsi2c30_bus>;
		clocks = <&clock USI13>, <&clock GATE_USI13>;
		clock-names = "rate_hsi2c", "gate_hsi2c";
		samsung,scl-clk-stretching;
		samsung,usi-i2c-v2;
		gpio_scl= <&gpg1 0 0x1>;
		gpio_sda= <&gpg1 1 0x1>;
		status = "disabled";
	};

	/* USI13_USI_I2C */
	hsi2c_31: hsi2c@10550000 {
		compatible = "samsung,exynos5-hsi2c";
		samsung,check-transdone-int;
		default-clk = <200000000>;
		reg = <0x0 0x10550000 0x1000>;
		interrupts = <0 INTREQ__USI13_I2C 0>;
		#address-cells = <1>;
		#size-cells = <0>;
		pinctrl-names = "default";
		pinctrl-0 = <&hsi2c31_bus>;
		clocks = <&clock PERIC0_USI_I2C>, <&clock GATE_USI13_I2C>;
		clock-names = "rate_hsi2c", "gate_hsi2c";
		samsung,scl-clk-stretching;
		samsung,usi-i2c-v2;
		gpio_scl= <&gpg1 2 0x1>;
		gpio_sda= <&gpg1 3 0x1>;
		status = "disabled";
	};

	/* USI14_USI */
	hsi2c_32: hsi2c@10560000 {
		compatible = "samsung,exynos5-hsi2c";
		samsung,check-transdone-int;
		default-clk = <200000000>;
		reg = <0x0 0x10560000 0x1000>;
		interrupts = <0 INTREQ__USI14_USI 0>;
		#address-cells = <1>;
		#size-cells = <0>;
		pinctrl-names = "default";
		pinctrl-0 = <&hsi2c32_bus>;
		clocks = <&clock USI14>, <&clock GATE_USI14>;
		clock-names = "rate_hsi2c", "gate_hsi2c";
		samsung,scl-clk-stretching;
		samsung,usi-i2c-v2;
		gpio_scl= <&gpg1 4 0x1>;
		gpio_sda= <&gpg1 5 0x1>;
		status = "disabled";
	};

	/* USI14_USI_I2C */
	hsi2c_33: hsi2c@10570000 {
		compatible = "samsung,exynos5-hsi2c";
		samsung,check-transdone-int;
		default-clk = <200000000>;
		reg = <0x0 0x10570000 0x1000>;
		interrupts = <0 INTREQ__USI14_I2C 0>;
		#address-cells = <1>;
		#size-cells = <0>;
		pinctrl-names = "default";
		pinctrl-0 = <&hsi2c33_bus>;
		clocks = <&clock PERIC0_USI_I2C>, <&clock GATE_USI14_I2C>;
		clock-names = "rate_hsi2c", "gate_hsi2c";
		samsung,scl-clk-stretching;
		samsung,usi-i2c-v2;
		gpio_scl= <&gpg1 6 0x1>;
		gpio_sda= <&gpg1 7 0x1>;
		status = "disabled";
	};

	/* USI_CMGP00 */
	hsi2c_34: hsi2c@14300000 {
		compatible = "samsung,exynos5-hsi2c";
		samsung,check-transdone-int;
		default-clk = <200000000>;
		reg = <0x0 0x14300000 0x1000>;
		interrupts = <0 INTREQ__USI_CMGP00 0>;
		#address-cells = <1>;
		#size-cells = <0>;
		pinctrl-names = "default";
		pinctrl-0 = <&hsi2c34_bus>;
		clocks = <&clock USI_CMGP00>, <&clock GATE_USI_CMGP00>;
		clock-names = "rate_hsi2c", "gate_hsi2c";
		samsung,scl-clk-stretching;
		samsung,usi-i2c-v2;
		gpio_scl= <&gpm0 0 0x1>;
		gpio_sda= <&gpm1 0 0x1>;
		status = "disabled";
	};

	/* USI_CMGP00_I2C */
	hsi2c_35: hsi2c@14310000 {
		compatible = "samsung,exynos5-hsi2c";
		samsung,check-transdone-int;
		default-clk = <200000000>;
		reg = <0x0 0x14310000 0x1000>;
		interrupts = <0 INTREQ__I2C_CMGP00 0>;
		#address-cells = <1>;
		#size-cells = <0>;
		pinctrl-names = "default";
		pinctrl-0 = <&hsi2c35_bus>;
		clocks = <&clock CMGP_USI_I2C>, <&clock GATE_I2C_CMGP00>;
		clock-names = "rate_hsi2c", "gate_hsi2c";
		samsung,scl-clk-stretching;
		samsung,usi-i2c-v2;
		gpio_scl= <&gpm2 0 0x1>;
		gpio_sda= <&gpm3 0 0x1>;
		status = "disabled";
	};

	/* USI_CMGP01 */
	hsi2c_36: hsi2c@14320000 {
		compatible = "samsung,exynos5-hsi2c";
		samsung,check-transdone-int;
		default-clk = <200000000>;
		reg = <0x0 0x14320000 0x1000>;
		interrupts = <0 INTREQ__USI_CMGP01 0>;
		#address-cells = <1>;
		#size-cells = <0>;
		pinctrl-names = "default";
		pinctrl-0 = <&hsi2c36_bus>;
		clocks = <&clock USI_CMGP01>, <&clock GATE_USI_CMGP01>;
		clock-names = "rate_hsi2c", "gate_hsi2c";
		samsung,scl-clk-stretching;
		samsung,usi-i2c-v2;
		gpio_scl= <&gpm4 0 0x1>;
		gpio_sda= <&gpm5 0 0x1>;
		status = "disabled";
	};

	/* USI_CMGP01_I2C */
	hsi2c_37: hsi2c@14330000 {
		compatible = "samsung,exynos5-hsi2c";
		samsung,check-transdone-int;
		default-clk = <200000000>;
		reg = <0x0 0x14330000 0x1000>;
		interrupts = <0 INTREQ__I2C_CMGP01 0>;
		#address-cells = <1>;
		#size-cells = <0>;
		pinctrl-names = "default";
		pinctrl-0 = <&hsi2c37_bus>;
		clocks = <&clock CMGP_USI_I2C>, <&clock GATE_I2C_CMGP01>;
		clock-names = "rate_hsi2c", "gate_hsi2c";
		samsung,scl-clk-stretching;
		samsung,usi-i2c-v2;
		gpio_scl= <&gpm6 0 0x1>;
		gpio_sda= <&gpm7 0 0x1>;
		status = "disabled";
	};

	/* USI_CMGP02 */
	hsi2c_38: hsi2c@14340000 {
		compatible = "samsung,exynos5-hsi2c";
		samsung,check-transdone-int;
		default-clk = <200000000>;
		reg = <0x0 0x14340000 0x1000>;
		interrupts = <0 INTREQ__USI_CMGP02 0>;
		#address-cells = <1>;
		#size-cells = <0>;
		pinctrl-names = "default";
		pinctrl-0 = <&hsi2c38_bus>;
		clocks = <&clock USI_CMGP02>, <&clock GATE_USI_CMGP02>;
		clock-names = "rate_hsi2c", "gate_hsi2c";
		samsung,scl-clk-stretching;
		samsung,usi-i2c-v2;
		gpio_scl= <&gpm10 0 0x1>;
		gpio_sda= <&gpm11 0 0x1>;
		status = "disabled";
	};

	/* USI_CMGP02_I2C */
	hsi2c_39: hsi2c@14350000 {
		compatible = "samsung,exynos5-hsi2c";
		samsung,check-transdone-int;
		default-clk = <200000000>;
		reg = <0x0 0x14350000 0x1000>;
		interrupts = <0 INTREQ__I2C_CMGP02 0>;
		#address-cells = <1>;
		#size-cells = <0>;
		pinctrl-names = "default";
		pinctrl-0 = <&hsi2c39_bus>;
		clocks = <&clock CMGP_USI_I2C>, <&clock GATE_I2C_CMGP02>;
		clock-names = "rate_hsi2c", "gate_hsi2c";
		samsung,scl-clk-stretching;
		samsung,usi-i2c-v2;
		gpio_scl= <&gpm12 0 0x1>;
		gpio_sda= <&gpm13 0 0x1>;
		status = "disabled";
	};

	/* USI_CMGP03 */
	hsi2c_40: hsi2c@14360000 {
		compatible = "samsung,exynos5-hsi2c";
		samsung,check-transdone-int;
		default-clk = <200000000>;
		reg = <0x0 0x14360000 0x1000>;
		interrupts = <0 INTREQ__USI_CMGP03 0>;
		#address-cells = <1>;
		#size-cells = <0>;
		pinctrl-names = "default";
		pinctrl-0 = <&hsi2c40_bus>;
		clocks = <&clock USI_CMGP03>, <&clock GATE_USI_CMGP03>;
		clock-names = "rate_hsi2c", "gate_hsi2c";
		samsung,scl-clk-stretching;
		samsung,usi-i2c-v2;
		gpio_scl= <&gpm14 0 0x1>;
		gpio_sda= <&gpm15 0 0x1>;
		status = "disabled";
	};

	/* USI_CMGP03_I2C */
	hsi2c_41: hsi2c@14370000 {
		compatible = "samsung,exynos5-hsi2c";
		samsung,check-transdone-int;
		default-clk = <200000000>;
		reg = <0x0 0x14370000 0x1000>;
		interrupts = <0 INTREQ__I2C_CMGP03 0>;
		#address-cells = <1>;
		#size-cells = <0>;
		pinctrl-names = "default";
		pinctrl-0 = <&hsi2c41_bus>;
		clocks = <&clock CMGP_USI_I2C>, <&clock GATE_I2C_CMGP03>;
		clock-names = "rate_hsi2c", "gate_hsi2c";
		samsung,scl-clk-stretching;
		samsung,usi-i2c-v2;
		gpio_scl= <&gpm16 0 0x1>;
		gpio_sda= <&gpm17 0 0x1>;
		status = "disabled";
	};

	/* USI_CHUB00 */
	hsi2c_42: hsi2c@13AC0000 {
		compatible = "samsung,exynos5-hsi2c";
		samsung,check-transdone-int;
		default-clk = <200000000>;
		reg = <0x0 0x13ac0000 0x1000>;
		interrupts = <0 INTREQ__USI_CHUB00 0>;
		#address-cells = <1>;
		#size-cells = <0>;
		pinctrl-names = "default";
		pinctrl-0 = <&hsi2c42_bus>;
		clocks = <&clock CHUB_USI00>, <&clock GATE_USI_CHUB00>;
		clock-names = "rate_hsi2c", "gate_hsi2c";
		samsung,scl-clk-stretching;
		samsung,usi-i2c-v2;
		gpio_scl= <&gph0 0 0x1>;
		gpio_sda= <&gph0 1 0x1>;
		status = "disabled";
	};

	/* USI_CHUB00_I2C */
	hsi2c_43: hsi2c@13AD0000 {
		compatible = "samsung,exynos5-hsi2c";
		samsung,check-transdone-int;
		default-clk = <200000000>;
		reg = <0x0 0x13ad0000 0x1000>;
		interrupts = <0 INTREQ__I2C_CHUB00 0>;
		#address-cells = <1>;
		#size-cells = <0>;
		pinctrl-names = "default";
		pinctrl-0 = <&hsi2c43_bus>;
		clocks = <&clock CHUB_USI_I2C>, <&clock GATE_I2C_CHUB00>;
		clock-names = "rate_hsi2c", "gate_hsi2c";
		samsung,scl-clk-stretching;
		samsung,usi-i2c-v2;
		gpio_scl= <&gph0 2 0x1>;
		gpio_sda= <&gph0 3 0x1>;
		status = "disabled";
	};

	/* USI_CHUB01 */
	hsi2c_44: hsi2c@13AE0000 {
		compatible = "samsung,exynos5-hsi2c";
		samsung,check-transdone-int;
		default-clk = <200000000>;
		reg = <0x0 0x13ae0000 0x1000>;
		interrupts = <0 INTREQ__USI_CHUB01 0>;
		#address-cells = <1>;
		#size-cells = <0>;
		pinctrl-names = "default";
		pinctrl-0 = <&hsi2c44_bus>;
		clocks = <&clock CHUB_USI01>, <&clock GATE_USI_CHUB01>;
		clock-names = "rate_hsi2c", "gate_hsi2c";
		samsung,scl-clk-stretching;
		samsung,usi-i2c-v2;
		gpio_scl= <&gph0 4 0x1>;
		gpio_sda= <&gph0 5 0x1>;
		status = "disabled";
	};

	/* USI_CHUB01_I2C */
	hsi2c_45: hsi2c@13AF0000 {
		compatible = "samsung,exynos5-hsi2c";
		samsung,check-transdone-int;
		default-clk = <200000000>;
		reg = <0x0 0x13af0000 0x1000>;
		interrupts = <0 INTREQ__I2C_CHUB01 0>;
		#address-cells = <1>;
		#size-cells = <0>;
		pinctrl-names = "default";
		pinctrl-0 = <&hsi2c45_bus>;
		clocks = <&clock CHUB_USI_I2C>, <&clock GATE_I2C_CHUB01>;
		clock-names = "rate_hsi2c", "gate_hsi2c";
		samsung,scl-clk-stretching;
		samsung,usi-i2c-v2;
		gpio_scl= <&gph0 6 0x1>;
		gpio_sda= <&gph0 7 0x1>;
		status = "disabled";
	};

	/* SPI USI_PERIC1_SPI_CAM0 */
	spi_0: spi@10850000 {
		compatible = "samsung,exynos-spi";
		reg = <0x0 0x10850000 0x100>;
		samsung,spi-fifosize = <256>;
		interrupts = <0 INTREQ__SPI_CAM0 0>;
/*
		dma-mode;
		dmas = <&pdma0 25 &pdma0 24>;
*/
		dma-names = "tx", "rx";
		swap-mode;
		#address-cells = <1>;
		#size-cells = <0>;
		clocks = <&clock GATE_SPI_CAM0>, <&clock SPI_CAM0>;
		clock-names = "spi", "spi_busclk0";
		pinctrl-names = "default";
		pinctrl-0 = <&spi0_bus>;
		status = "disabled";
	};

	/* SPI USI_PERIC0_USI00_SPI */
	spi_1: spi@10450000 {
		compatible = "samsung,exynos-spi";
		reg = <0x0 0x10450000 0x100>;
		samsung,spi-fifosize = <64>;
		interrupts = <0 INTREQ__USI00_USI 0>;
/*
		dma-mode;
		dmas = <&pdma0 1 &pdma0 0>;
*/
		dma-names = "tx", "rx";
		swap-mode;
		#address-cells = <1>;
		#size-cells = <0>;
		clocks = <&clock GATE_USI00>, <&clock USI00>;
		clock-names = "spi", "spi_busclk0";
		pinctrl-names = "default";
		pinctrl-0 = <&spi1_bus>;
		status = "disabled";
	};

	/* SPI USI_PERIC0_USI01_SPI */
	spi_2: spi@10470000 {
		compatible = "samsung,exynos-spi";
		reg = <0x0 0x10470000 0x100>;
		samsung,spi-fifosize = <64>;
		interrupts = <0 INTREQ__USI01_USI 0>;
/*
		dma-mode;
		dmas = <&pdma0 3 &pdma0 2>;
*/
		dma-names = "tx", "rx";
		swap-mode;
		#address-cells = <1>;
		#size-cells = <0>;
		clocks = <&clock GATE_USI01>, <&clock USI01>;
		clock-names = "spi", "spi_busclk0";
		pinctrl-names = "default";
		pinctrl-0 = <&spi2_bus>;
		status = "disabled";
	};

	/* SPI USI_PERIC0_USI02_SPI */
	spi_3: spi@10490000 {
		compatible = "samsung,exynos-spi";
		reg = <0x0 0x10490000 0x100>;
		samsung,spi-fifosize = <64>;
		interrupts = <0 INTREQ__USI02_USI 0>;
/*
		dma-mode;
		dmas = <&pdma0 5 &pdma0 4>;
*/
		dma-names = "tx", "rx";
		swap-mode;
		#address-cells = <1>;
		#size-cells = <0>;
		clocks = <&clock GATE_USI02>, <&clock USI02>;
		clock-names = "spi", "spi_busclk0";
		pinctrl-names = "default";
		pinctrl-0 = <&spi3_bus>;
		status = "disabled";
	};

	/* SPI USI_PERIC0_USI03_SPI */
	spi_4: spi@104B0000 {
		compatible = "samsung,exynos-spi";
		reg = <0x0 0x104B0000 0x100>;
		samsung,spi-fifosize = <64>;
		interrupts = <0 INTREQ__USI03_USI 0>;
/*
		dma-mode;
		dmas = <&pdma0 7 &pdma0 6>;
*/
		dma-names = "tx", "rx";
		swap-mode;
		#address-cells = <1>;
		#size-cells = <0>;
		clocks = <&clock GATE_USI03>, <&clock USI03>;
		clock-names = "spi", "spi_busclk0";
		pinctrl-names = "default";
		pinctrl-0 = <&spi4_bus>;
		status = "disabled";
	};

	/* SPI USI_PERIC0_USI04_SPI */
	spi_5: spi@104D0000 {
		compatible = "samsung,exynos-spi";
		reg = <0x0 0x104D0000 0x100>;
		samsung,spi-fifosize = <64>;
		interrupts = <0 INTREQ__USI04_USI 0>;
/*
		dma-mode;
		dmas = <&pdma0 9 &pdma0 8>;
*/
		dma-names = "tx", "rx";
		swap-mode;
		#address-cells = <1>;
		#size-cells = <0>;
		clocks = <&clock GATE_USI04>, <&clock USI04>;
		clock-names = "spi", "spi_busclk0";
		pinctrl-names = "default";
		pinctrl-0 = <&spi5_bus>;
		status = "disabled";
	};

	/* SPI USI_PERIC0_USI05_SPI */
	spi_6: spi@104F0000 {
		compatible = "samsung,exynos-spi";
		reg = <0x0 0x104F0000 0x100>;
		samsung,spi-fifosize = <64>;
		interrupts = <0 INTREQ__USI05_USI 0>;
/*
		dma-mode;
		dmas = <&pdma0 11 &pdma0 10>;
*/
		dma-names = "tx", "rx";
		swap-mode;
		#address-cells = <1>;
		#size-cells = <0>;
		clocks = <&clock GATE_USI05>, <&clock USI05>;
		clock-names = "spi", "spi_busclk0";
		pinctrl-names = "default";
		pinctrl-0 = <&spi6_bus>;
		status = "disabled";
	};

	/* SPI USI_PERIC1_USI06_SPI */
	spi_7: spi@108A0000 {
		compatible = "samsung,exynos-spi";
		reg = <0x0 0x108A0000 0x100>;
		samsung,spi-fifosize = <64>;
		interrupts = <0 INTREQ__USI06_USI 0>;
/*
		dma-mode;
		dmas = <&pdma0 15 &pdma0 14>;
*/
		dma-names = "tx", "rx";
		swap-mode;
		#address-cells = <1>;
		#size-cells = <0>;
		clocks = <&clock GATE_USI06>, <&clock USI06>;
		clock-names = "spi", "spi_busclk0";
		pinctrl-names = "default";
		pinctrl-0 = <&spi7_bus>;
		status = "disabled";
	};

	/* SPI USI_PERIC1_USI07_SPI */
	spi_8: spi@108C0000 {
		compatible = "samsung,exynos-spi";
		reg = <0x0 0x108C0000 0x100>;
		samsung,spi-fifosize = <64>;
		interrupts = <0 INTREQ__USI07_USI 0>;
/*
		dma-mode;
		dmas = <&pdma0 17 &pdma0 16>;
*/
		dma-names = "tx", "rx";
		swap-mode;
		#address-cells = <1>;
		#size-cells = <0>;
		clocks = <&clock GATE_USI07>, <&clock USI07>;
		clock-names = "spi", "spi_busclk0";
		pinctrl-names = "default";
		pinctrl-0 = <&spi8_bus>;
		status = "disabled";
	};

	/* SPI USI_PERIC1_USI08_SPI */
	spi_9: spi@108E0000 {
		compatible = "samsung,exynos-spi";
		reg = <0x0 0x108E0000 0x100>;
		samsung,spi-fifosize = <256>;
		interrupts = <0 INTREQ__USI08_USI 0>;
/*
		dma-mode;
		dmas = <&pdma0 19 &pdma0 18>;
*/
		dma-names = "tx", "rx";
		swap-mode;
		#address-cells = <1>;
		#size-cells = <0>;
		clocks = <&clock GATE_USI08>, <&clock USI08>;
		clock-names = "spi", "spi_busclk0";
		pinctrl-names = "default";
		pinctrl-0 = <&spi9_bus>;
		status = "disabled";
	};

	/* SPI USI_PERIC1_USI09_SPI */
	spi_10: spi@10900000 {
		compatible = "samsung,exynos-spi";
		reg = <0x0 0x10900000 0x100>;
		samsung,spi-fifosize = <256>;
		interrupts = <0 INTREQ__USI09_USI 0>;
/*
		dma-mode;
		dmas = <&pdma0 21 &pdma0 20>;
*/
		dma-names = "tx", "rx";
		swap-mode;
		#address-cells = <1>;
		#size-cells = <0>;
		clocks = <&clock GATE_USI09>, <&clock USI09>;
		clock-names = "spi", "spi_busclk0";
		pinctrl-names = "default";
		pinctrl-0 = <&spi10_bus>;
		status = "disabled";
	};

	/* SPI USI_PERIC1_USI10_SPI */
	spi_11: spi@10920000 {
		compatible = "samsung,exynos-spi";
		reg = <0x0 0x10920000 0x100>;
		samsung,spi-fifosize = <256>;
		interrupts = <0 INTREQ__USI10_USI 0>;
/*
		dma-mode;
		dmas = <&pdma0 23 &pdma0 22>;
*/
		dma-names = "tx", "rx";
		swap-mode;
		#address-cells = <1>;
		#size-cells = <0>;
		clocks = <&clock GATE_USI10>, <&clock USI10>;
		clock-names = "spi", "spi_busclk0";
		pinctrl-names = "default";
		pinctrl-0 = <&spi11_bus>;
		status = "disabled";
	};

	/* SPI USI_PERIC1_USI11_SPI */
	spi_12: spi@10940000 {
		compatible = "samsung,exynos-spi";
		reg = <0x0 0x10940000 0x100>;
		samsung,spi-fifosize = <64>;
		interrupts = <0 INTREQ__USI11_USI 0>;
/*
		dma-mode;
		dmas = <&pdma0 31 &pdma0 30>;
*/
		dma-names = "tx", "rx";
		swap-mode;
		#address-cells = <1>;
		#size-cells = <0>;
		clocks = <&clock GATE_USI11>, <&clock USI11>;
		clock-names = "spi", "spi_busclk0";
		pinctrl-names = "default";
		pinctrl-0 = <&spi12_bus>;
		status = "disabled";
	};

	/* SPI USI_PERIC0_USI12_SPI */
	spi_13: spi@10520000 {
		compatible = "samsung,exynos-spi";
		reg = <0x0 0x10520000 0x100>;
		samsung,spi-fifosize = <64>;
		interrupts = <0 INTREQ__USI12_USI 0>;
/*
		dma-mode;
		dmas = <&pdma0 31 &pdma0 30>;
*/
		dma-names = "tx", "rx";
		swap-mode;
		#address-cells = <1>;
		#size-cells = <0>;
		clocks = <&clock GATE_USI12>, <&clock USI12>;
		clock-names = "spi", "spi_busclk0";
		pinctrl-names = "default";
		pinctrl-0 = <&spi13_bus>;
		status = "disabled";
	};

	/* SPI USI_PERIC0_USI13_SPI */
	spi_14: spi@10540000 {
		compatible = "samsung,exynos-spi";
		reg = <0x0 0x10540000 0x100>;
		samsung,spi-fifosize = <64>;
		interrupts = <0 INTREQ__USI13_USI 0>;
/*
		dma-mode;
		dmas = <&pdma0 31 &pdma0 30>;
*/
		dma-names = "tx", "rx";
		swap-mode;
		#address-cells = <1>;
		#size-cells = <0>;
		clocks = <&clock GATE_USI13>, <&clock USI13>;
		clock-names = "spi", "spi_busclk0";
		pinctrl-names = "default";
		pinctrl-0 = <&spi14_bus>;
		status = "disabled";
	};

	/* SPI USI_PERIC0_USI14_SPI */
	spi_15: spi@10560000 {
		compatible = "samsung,exynos-spi";
		reg = <0x0 0x10560000 0x100>;
		samsung,spi-fifosize = <64>;
		interrupts = <0 INTREQ__USI14_USI 0>;
/*
		dma-mode;
		dmas = <&pdma0 31 &pdma0 30>;
*/
		dma-names = "tx", "rx";
		swap-mode;
		#address-cells = <1>;
		#size-cells = <0>;
		clocks = <&clock GATE_USI14>, <&clock USI14>;
		clock-names = "spi", "spi_busclk0";
		pinctrl-names = "default";
		pinctrl-0 = <&spi15_bus>;
		status = "disabled";
	};

	/* SPI USI_CMGP00 */
	spi_16: spi@14300000 {
		compatible = "samsung,exynos-spi";
		reg = <0x0 0x14300000 0x100>;
		samsung,spi-fifosize = <64>;
		interrupts = <0 INTREQ__USI_CMGP00 0>;
/*
		dma-mode;
		dmas = <&pdma0 31 &pdma0 30>;
*/
		dma-names = "tx", "rx";
		swap-mode;
		#address-cells = <1>;
		#size-cells = <0>;
		clocks = <&clock GATE_USI_CMGP00>, <&clock USI_CMGP00>;
		clock-names = "spi", "spi_busclk0";
		pinctrl-names = "default";
		pinctrl-0 = <&spi16_bus>;
		status = "disabled";
	};

	/* SPI USI_CMGP01 */
	spi_17: spi@14320000 {
		compatible = "samsung,exynos-spi";
		reg = <0x0 0x1432000 0x100>;
		samsung,spi-fifosize = <64>;
		interrupts = <0 INTREQ__USI_CMGP01 0>;
/*
		dma-mode;
		dmas = <&pdma0 31 &pdma0 30>;
*/
		dma-names = "tx", "rx";
		swap-mode;
		#address-cells = <1>;
		#size-cells = <0>;
		clocks = <&clock GATE_USI_CMGP01>, <&clock USI_CMGP01>;
		clock-names = "spi", "spi_busclk0";
		pinctrl-names = "default";
		pinctrl-0 = <&spi17_bus>;
		status = "disabled";
	};

	/* SPI USI_CMGP02 */
	spi_18: spi@14340000 {
		compatible = "samsung,exynos-spi";
		reg = <0x0 0x14340000 0x100>;
		samsung,spi-fifosize = <64>;
		interrupts = <0 INTREQ__USI_CMGP02 0>;
/*
		dma-mode;
		dmas = <&pdma0 31 &pdma0 30>;
*/
		dma-names = "tx", "rx";
		swap-mode;
		#address-cells = <1>;
		#size-cells = <0>;
		clocks = <&clock GATE_USI_CMGP02>, <&clock USI_CMGP02>;
		clock-names = "spi", "spi_busclk0";
		pinctrl-names = "default";
		pinctrl-0 = <&spi18_bus>;
		status = "disabled";
	};

	/* SPI USI_CMGP03 */
	spi_19: spi@14360000 {
		compatible = "samsung,exynos-spi";
		reg = <0x0 0x14360000 0x100>;
		samsung,spi-fifosize = <64>;
		interrupts = <0 INTREQ__USI_CMGP03 0>;
/*
		dma-mode;
		dmas = <&pdma0 31 &pdma0 30>;
*/
		dma-names = "tx", "rx";
		swap-mode;
		#address-cells = <1>;
		#size-cells = <0>;
		clocks = <&clock GATE_USI_CMGP03>, <&clock USI_CMGP03>;
		clock-names = "spi", "spi_busclk0";
		pinctrl-names = "default";
		pinctrl-0 = <&spi19_bus>;
		status = "disabled";
	};

	/* SPI USI_CHUB00 */
	spi_20: spi@13AC0000 {
		compatible = "samsung,exynos-spi";
		reg = <0x0 0x13ac0000 0x100>;
		samsung,spi-fifosize = <64>;
		interrupts = <0 INTREQ__USI_CHUB00 0>;
/*
		dma-mode;
		dmas = <&pdma0 31 &pdma0 30>;
*/
		dma-names = "tx", "rx";
		swap-mode;
		#address-cells = <1>;
		#size-cells = <0>;
		clocks = <&clock GATE_USI_CHUB00>, <&clock CHUB_USI00>;
		clock-names = "spi", "spi_busclk0";
		pinctrl-names = "default";
		pinctrl-0 = <&spi20_bus>;
		status = "disabled";
	};

	/* SPI USI_CHUB01 */
	spi_21: spi@13AE0000 {
		compatible = "samsung,exynos-spi";
		reg = <0x0 0x13AE0000 0x100>;
		samsung,spi-fifosize = <64>;
		interrupts = <0 INTREQ__USI_CHUB01 0>;
/*
		dma-mode;
		dmas = <&pdma0 31 &pdma0 30>;
*/
		dma-names = "tx", "rx";
		swap-mode;
		#address-cells = <1>;
		#size-cells = <0>;
		clocks = <&clock GATE_USI_CHUB01>, <&clock CHUB_USI01>;
		clock-names = "spi", "spi_busclk0";
		pinctrl-names = "default";
		pinctrl-0 = <&spi21_bus>;
		status = "disabled";
	};

	/* USI_PERIC0_UART_DBG */
	serial_0: uart@10440000 {
		compatible = "samsung,exynos-uart";
		samsung,separate-uart-clk;
		reg = <0x0 0x10440000 0x100>;
		samsung,fifo-size = <256>;
		interrupts = <0 INTREQ__UART_DBG 0>;
		pinctrl-names = "default";
		pinctrl-0 = <&uart0_bus>;
		samsung,usi-serial-v2;
		clocks = <&clock GATE_UART_DBG>, <&clock UART_DBG>;
		clock-names = "gate_pclk0", "gate_uart0";
		status = "disabled";
	};

	/* USI_PERIC1_UART_BT */
	serial_1: uart@10840000 {
		compatible = "samsung,exynos-uart";
		samsung,separate-uart-clk;
		reg = <0x0 0x10840000 0x100>;
		samsung,fifo-size = <256>;
		interrupts = <0 INTREQ__UART_BT 0>;
		pinctrl-names = "default";
		pinctrl-0 = <&uart1_bus_single &uart1_rxd_pull>; /* or _bus_dual */
		samsung,usi-serial-v2;
		clocks = <&clock GATE_UART_BT>, <&clock UART_BT>;
		clock-names = "gate_pclk1", "gate_uart1";
		status = "disabled";
	};

	/* USI_PERIC0_USI00_UART */
	serial_2: uart@10450000 {
		compatible = "samsung,exynos-uart";
		samsung,separate-uart-clk;
		reg = <0x0 0x10450000 0x100>;
		samsung,fifo-size = <64>;
		interrupts = <0 INTREQ__USI00_USI 0>;
		pinctrl-names = "default";
		pinctrl-0 = <&uart2_bus_single>; /* or _bus_dual */
		samsung,usi-serial-v2;
		clocks = <&clock GATE_USI00>, <&clock USI00>;
		clock-names = "gate_pclk2", "gate_uart2";
		status = "disabled";
	};

	/* USI_PERIC0_USI01_UART */
	serial_3: uart@10470000 {
		compatible = "samsung,exynos-uart";
		samsung,separate-uart-clk;
		reg = <0x0 0x10470000 0x100>;
		samsung,fifo-size = <64>;
		interrupts = <0 INTREQ__USI01_USI 0>;
		pinctrl-names = "default";
		pinctrl-0 = <&uart3_bus_single>; /* or _bus_dual */
		samsung,usi-serial-v2;
		clocks = <&clock GATE_USI01>, <&clock USI01>;
		clock-names = "gate_pclk3", "gate_uart3";
		status = "disabled";
	};

	/* USI_PERIC0_USI02_UART */
	serial_4: uart@10490000 {
		compatible = "samsung,exynos-uart";
		samsung,separate-uart-clk;
		reg = <0x0 0x10490000 0x100>;
		samsung,fifo-size = <64>;
		interrupts = <0 INTREQ__USI02_USI 0>;
		pinctrl-names = "default";
		pinctrl-0 = <&uart4_bus_single>; /* or _bus_dual */
		samsung,usi-serial-v2;
		clocks = <&clock GATE_USI02>, <&clock USI02>;
		clock-names = "gate_pclk4", "gate_uart4";
		status = "disabled";
	};

	/* USI_PERIC0_USI03_UART */
	serial_5: uart@104B0000 {
		compatible = "samsung,exynos-uart";
		samsung,separate-uart-clk;
		reg = <0x0 0x104B0000 0x100>;
		samsung,fifo-size = <64>;
		interrupts = <0 INTREQ__USI03_USI 0>;
		pinctrl-names = "default";
		pinctrl-0 = <&uart5_bus_single>; /* or _bus_dual */
		samsung,usi-serial-v2;
		clocks = <&clock GATE_USI03>, <&clock USI03>;
		clock-names = "gate_pclk5", "gate_uart5";
		status = "disabled";
	};

	/* USI_PERIC0_USI04_UART */
	serial_6: uart@104D0000 {
		compatible = "samsung,exynos-uart";
		samsung,separate-uart-clk;
		reg = <0x0 0x104D0000 0x100>;
		samsung,fifo-size = <64>;
		interrupts = <0 INTREQ__USI04_USI 0>;
		pinctrl-names = "default";
		pinctrl-0 = <&uart6_bus_single>; /* or _bus_dual */
		samsung,usi-serial-v2;
		clocks = <&clock GATE_USI04>, <&clock USI04>;
		clock-names = "gate_pclk6", "gate_uart6";
		status = "disabled";
	};

	/* USI_PERIC0_USI05_UART */
	serial_7: uart@104F0000 {
		compatible = "samsung,exynos-uart";
		samsung,separate-uart-clk;
		reg = <0x0 0x104F0000 0x100>;
		samsung,fifo-size = <64>;
		interrupts = <0 INTREQ__USI05_USI 0>;
		pinctrl-names = "default";
		pinctrl-0 = <&uart7_bus_single>; /* or _bus_dual */
		samsung,usi-serial-v2;
		clocks = <&clock GATE_USI05>, <&clock USI05>;
		clock-names = "gate_pclk7", "gate_uart7";
		status = "disabled";
	};

	/* USI_PERIC1_USI06_UART */
	serial_8: uart@108A0000 {
		compatible = "samsung,exynos-uart";
		samsung,separate-uart-clk;
		reg = <0x0 0x108A0000 0x100>;
		samsung,fifo-size = <64>;
		interrupts = <0 INTREQ__USI06_USI 0>;
		pinctrl-names = "default";
		pinctrl-0 = <&uart8_bus_single>; /* or _bus_dual */
		samsung,usi-serial-v2;
		clocks = <&clock GATE_USI06>, <&clock USI06>;
		clock-names = "gate_pclk8", "gate_uart8";
		status = "disabled";
	};

	/* USI_PERIC1_USI07_UART */
	serial_9: uart@108C0000 {
		compatible = "samsung,exynos-uart";
		samsung,separate-uart-clk;
		reg = <0x0 0x108C0000 0x100>;
		samsung,fifo-size = <64>;
		interrupts = <0 INTREQ__USI07_USI 0>;
		pinctrl-names = "default";
		pinctrl-0 = <&uart9_bus_single>; /* or _bus_dual */
		samsung,usi-serial-v2;
		clocks = <&clock GATE_USI07>, <&clock USI07>;
		clock-names = "gate_pclk9", "gate_uart9";
		status = "disabled";
	};

	/* USI_PERIC1_USI08_UART */
	serial_10: uart@108E0000 {
		compatible = "samsung,exynos-uart";
		samsung,separate-uart-clk;
		reg = <0x0 0x108E0000 0x100>;
		samsung,fifo-size = <256>;
		interrupts = <0 INTREQ__USI08_USI 0>;
		pinctrl-names = "default";
		pinctrl-0 = <&uart10_bus_single>; /* or _bus_dual */
		samsung,usi-serial-v2;
		clocks = <&clock GATE_USI08>, <&clock USI08>;
		clock-names = "gate_pclk10", "gate_uart10";
		status = "disabled";
	};

	/* USI_PERIC1_USI09_UART */
	serial_11: uart@10900000 {
		compatible = "samsung,exynos-uart";
		samsung,separate-uart-clk;
		reg = <0x0 0x10900000 0x100>;
		samsung,fifo-size = <256>;
		interrupts = <0 INTREQ__USI09_USI 0>;
		pinctrl-names = "default";
		pinctrl-0 = <&uart11_bus_single>; /* or _bus_dual */
		samsung,usi-serial-v2;
		clocks = <&clock GATE_USI09>, <&clock USI09>;
		clock-names = "gate_pclk11", "gate_uart11";
		status = "disabled";
	};

	/* USI_PERIC1_USI10_UART */
	serial_12: uart@10920000 {
		compatible = "samsung,exynos-uart";
		samsung,separate-uart-clk;
		reg = <0x0 0x10920000 0x100>;
		samsung,fifo-size = <256>;
		interrupts = <0 INTREQ__USI10_USI 0>;
		pinctrl-names = "default";
		pinctrl-0 = <&uart12_bus_single>; /* or _bus_dual */
		samsung,usi-serial-v2;
		clocks = <&clock GATE_USI10>, <&clock USI10>;
		clock-names = "gate_pclk12", "gate_uart12";
		status = "disabled";
	};

	/* USI_PERIC1_USI11_UART */
	serial_13: uart@10940000 {
		compatible = "samsung,exynos-uart";
		samsung,separate-uart-clk;
		reg = <0x0 0x10940000 0x100>;
		samsung,fifo-size = <64>;
		interrupts = <0 INTREQ__USI11_USI 0>;
		pinctrl-names = "default";
		pinctrl-0 = <&uart13_bus_single>; /* or _bus_dual */
		samsung,usi-serial-v2;
		clocks = <&clock GATE_USI11>, <&clock USI11>;
		clock-names = "gate_pclk13", "gate_uart13";
		status = "disabled";
	};

	/* USI_PERIC0_USI12_UART */
	serial_14: uart@10520000 {
		compatible = "samsung,exynos-uart";
		samsung,separate-uart-clk;
		reg = <0x0 0x10520000 0x100>;
		samsung,fifo-size = <64>;
		interrupts = <0 INTREQ__USI12_USI 0>;
		pinctrl-names = "default";
		pinctrl-0 = <&uart14_bus_single>; /* or _bus_dual */
		samsung,usi-serial-v2;
		clocks = <&clock GATE_USI12>, <&clock USI12>;
		clock-names = "gate_pclk14", "gate_uart14";
		status = "disabled";
	};

	/* USI_PERIC0_USI13_UART */
	serial_15: uart@10540000 {
		compatible = "samsung,exynos-uart";
		samsung,separate-uart-clk;
		reg = <0x0 0x10540000 0x100>;
		samsung,fifo-size = <64>;
		interrupts = <0 INTREQ__USI13_USI 0>;
		pinctrl-names = "default";
		pinctrl-0 = <&uart15_bus_single>; /* or _bus_dual */
		samsung,usi-serial-v2;
		clocks = <&clock GATE_USI13>, <&clock USI13>;
		clock-names = "gate_pclk15", "gate_uart15";
		status = "disabled";
	};

	/* USI_PERIC0_USI14_UART */
	serial_16: uart@10560000 {
		compatible = "samsung,exynos-uart";
		samsung,separate-uart-clk;
		reg = <0x0 0x10560000 0x100>;
		samsung,fifo-size = <64>;
		interrupts = <0 INTREQ__USI14_USI 0>;
		pinctrl-names = "default";
		pinctrl-0 = <&uart16_bus_single>; /* or _bus_dual */
		samsung,usi-serial-v2;
		clocks = <&clock GATE_USI14>, <&clock USI14>;
		clock-names = "gate_pclk16", "gate_uart16";
		status = "disabled";
	};

	/* USI_CMGP00_UART */
	serial_17: uart@14300000 {
		compatible = "samsung,exynos-uart";
		samsung,separate-uart-clk;
		reg = <0x0 0x14300000 0x100>;
		samsung,fifo-size = <64>;
		interrupts = <0 INTREQ__USI_CMGP00 0>;
		pinctrl-names = "default";
		pinctrl-0 = <&uart17_bus_single>; /* or _bus_dual */
		samsung,usi-serial-v2;
		clocks = <&clock GATE_USI_CMGP00>, <&clock USI_CMGP00>;
		clock-names = "gate_pclk17", "gate_uart17";
		status = "disabled";
	};

	/* USI_CMGP01_UART */
	serial_18: uart@14320000 {
		compatible = "samsung,exynos-uart";
		samsung,separate-uart-clk;
		reg = <0x0 0x14320000 0x100>;
		samsung,fifo-size = <64>;
		interrupts = <0 INTREQ__USI_CMGP01 0>;
		pinctrl-names = "default";
		pinctrl-0 = <&uart18_bus_single>; /* or _bus_dual */
		samsung,usi-serial-v2;
		clocks = <&clock GATE_USI_CMGP01>, <&clock USI_CMGP01>;
		clock-names = "gate_pclk18", "gate_uart18";
		status = "disabled";
	};

	/* USI_CMGP02_UART */
	serial_19: uart@14340000 {
		compatible = "samsung,exynos-uart";
		samsung,separate-uart-clk;
		reg = <0x0 0x14340000 0x100>;
		samsung,fifo-size = <64>;
		interrupts = <0 INTREQ__USI_CMGP02 0>;
		pinctrl-names = "default";
		pinctrl-0 = <&uart19_bus_single>; /* or _bus_dual */
		samsung,usi-serial-v2;
		clocks = <&clock GATE_USI_CMGP02>, <&clock USI_CMGP02>;
		clock-names = "gate_pclk19", "gate_uart10";
		status = "disabled";
	};

	/* USI_CMGP03_UART */
	serial_20: uart@14360000 {
		compatible = "samsung,exynos-uart";
		samsung,separate-uart-clk;
		reg = <0x0 0x14360000 0x100>;
		samsung,fifo-size = <64>;
		interrupts = <0 INTREQ__USI_CMGP03 0>;
		pinctrl-names = "default";
		pinctrl-0 = <&uart20_bus_single>; /* or _bus_dual */
		samsung,usi-serial-v2;
		clocks = <&clock GATE_USI_CMGP03>, <&clock USI_CMGP03>;
		clock-names = "gate_pclk20", "gate_uart20";
		status = "disabled";
	};

	/* USI_CHUB00_UART */
	serial_21: uart@13AC0000 {
		compatible = "samsung,exynos-uart";
		samsung,separate-uart-clk;
		reg = <0x0 0x13ac0000 0x100>;
		samsung,fifo-size = <64>;
		interrupts = <0 INTREQ__USI_CHUB00 0>;
		pinctrl-names = "default";
		pinctrl-0 = <&uart21_bus_single>; /* or _bus_dual */
		samsung,usi-serial-v2;
		clocks = <&clock GATE_USI_CHUB00>, <&clock CHUB_USI00>;
		clock-names = "gate_pclk21", "gate_uart21";
		status = "disabled";
	};

	/* USI_CHUB01_UART */
	serial_22: uart@13AE0000 {
		compatible = "samsung,exynos-uart";
		samsung,separate-uart-clk;
		reg = <0x0 0x13ae0000 0x100>;
		samsung,fifo-size = <64>;
		interrupts = <0 INTREQ__USI_CHUB01 0>;
		pinctrl-names = "default";
		pinctrl-0 = <&uart22_bus_single>; /* or _bus_dual */
		samsung,usi-serial-v2;
		clocks = <&clock GATE_USI_CHUB01>, <&clock CHUB_USI01>;
		clock-names = "gate_pclk22", "gate_uart22";
		status = "disabled";
	};
};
